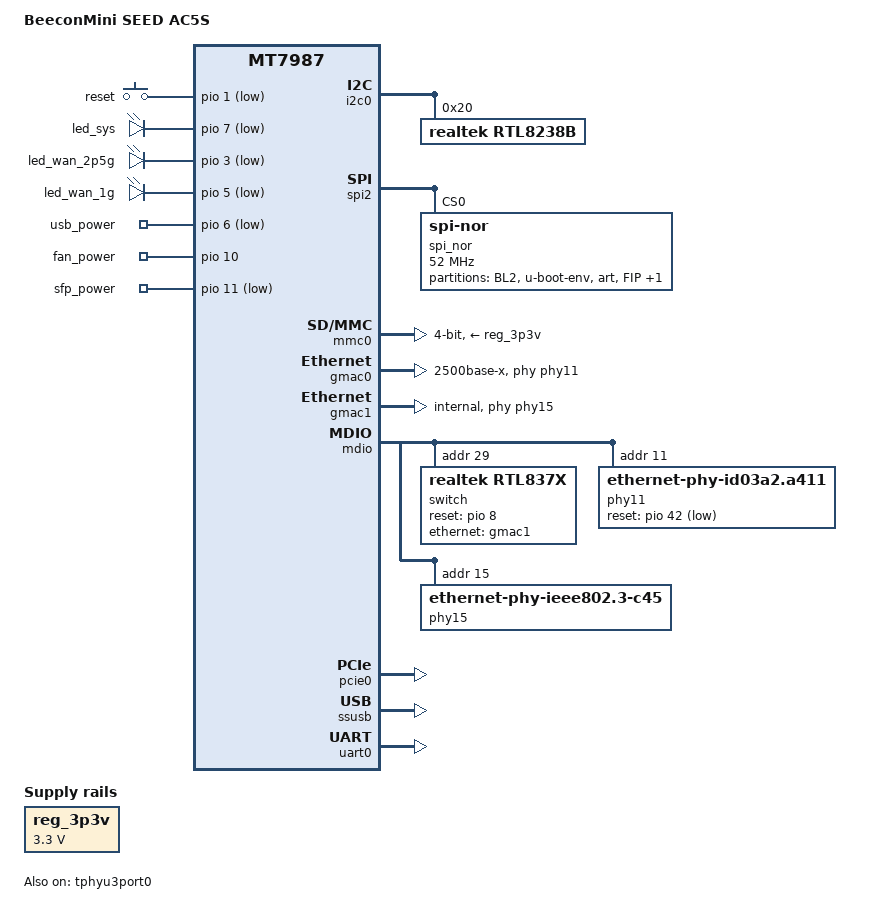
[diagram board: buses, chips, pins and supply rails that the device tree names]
// SPDX-License-Identifier: (GPL-2.0 OR MIT)
//
// BeeconMini SEED AC5S (NOR 变体, 固件放 SPI-NOR) — kernel 6.18 / immortalwrt
// 基准: BeeconMini/immortalwrt 25.12.1 分支同名 DTS
// 改动: 交换芯片节点转换为社区开源驱动 rtl837x-gsw 的绑定

/dts-v1/;
#include "mt7987a.dtsi"
#include <dt-bindings/input/input.h>

/ {
	model = "BeeconMini SEED AC5S";
	compatible = "beeconmini,seed-ac5s-nor", "mediatek,mt7987a", "mediatek,mt7987";

	aliases {
		label-mac-device = &gmac0;
		led-boot = &led_power;
		led-failsafe = &led_power;
		led-running = &led_power;
		led-upgrade = &led_power;
	};

	chosen {
		bootargs = "console=ttyS0,115200n1 \
			    earlycon=uart8250,mmio32,0x11000000 \
			    pci=pcie_bus_perf fstools_ignore_partname=1";
	};

	aliases {
		led-boot = &led_sys;
		led-failsafe = &led_sys;
		led-running = &led_sys;
		led-upgrade = &led_sys;
	};

	gpio-keys {
		compatible = "gpio-keys";

		reset {
			label = "reset";
			linux,code = <KEY_RESTART>;
			gpios = <&pio 1 GPIO_ACTIVE_LOW>;
			debounce-interval = <10>;
		};
	};

	gpio-leds {
		compatible = "gpio-leds";

		led_sys: led@0 {
			label = "led_sys";
			gpios = <&pio 7 GPIO_ACTIVE_LOW>;
		};

		led_wan_2p5g: led@1 {
			label = "led_wan_2p5g";
			gpios = <&pio 3 GPIO_ACTIVE_LOW>;
		};

		led_wan_1g: led@2 {
			label = "led_wan_1g";
			gpios = <&pio 5 GPIO_ACTIVE_LOW>;
		};
	};

	gpio-export {
		compatible = "gpio-export";
		#size-cells = <0>;

		usb {
			gpio-export,name = "usb_power";
			gpio-export,output = <0>;
			gpios = <&pio 6 GPIO_ACTIVE_LOW>;
		};

		fan {
			gpio-export,name = "fan_power";
			gpio-export,output = <0>;
			gpios = <&pio 10 GPIO_ACTIVE_HIGH>;
		};

		sfp {
			gpio-export,name = "sfp_power";
			gpio-export,output = <0>;
			gpios = <&pio 11 GPIO_ACTIVE_LOW>;
		};
	};

	reg_3p3v: regulator-3p3v {
		compatible = "regulator-fixed";
		regulator-name = "fixed-3.3V";
		regulator-min-microvolt = <3300000>;
		regulator-max-microvolt = <3300000>;
		regulator-boot-on;
		regulator-always-on;
	};
};

&i2c0 {
	status = "okay";
	rtl8238b: rtl8238b@20 {
		compatible = "realtek,rtl8238b";
		reg = <0x20>;
	};
};

&spi1 {
	status = "disabled";
};

&spi2 {
	status = "okay";

	spi_nor: spi_nor@0 {
		#address-cells = <1>;
		#size-cells = <1>;
		compatible = "jedec,spi-nor";
		reg = <0>;
		spi-max-frequency = <52000000>;
		spi-tx-bus-width = <4>;
		spi-rx-bus-width = <4>;

		partitions {
			compatible = "fixed-partitions";
			#address-cells = <1>;
			#size-cells = <1>;

			partition@00000 {
				label = "BL2";
				reg = <0x00000 0x0040000>;
				read-only;
			};

			partition@40000 {
				label = "u-boot-env";
				reg = <0x40000 0x0010000>;
			};

			art: partition@50000 {
				label = "art";
				reg = <0x50000 0x0010000>;

				nvmem-layout {
					compatible = "fixed-layout";
					#address-cells = <1>;
					#size-cells = <1>;

					macaddr_base: macaddr@0 {
						reg = <0x0 0x6>;
						compatible = "mac-base";
						#nvmem-cell-cells = <1>;
					};
				};
			};

			partition@60000 {
				label = "FIP";
				reg = <0x60000 0x0200000>;
				read-only;
			};

			partition@260000 {
				compatible = "denx,fit";
				label = "firmware";
				reg = <0x260000 0x1da0000>;
			};
		};
	};
};

&mmc0 {
	pinctrl-names = "default", "state_uhs";
	pinctrl-0 = <&mmc_pins_default>;
	pinctrl-1 = <&mmc_pins_uhs>;
	bus-width = <4>;
	max-frequency = <48000000>;
	cap-sd-highspeed;
	no-mmc;
	no-sdio;
	vmmc-supply = <&reg_3p3v>;
	vqmmc-supply = <&reg_3p3v>;
	status = "okay";
	#address-cells = <1>;
	#size-cells = <0>;
};

&gmac0 {
	compatible = "mediatek,eth-mac";
	reg = <0>;
	mac-type = "gdm";
	phy-mode = "2500base-x";
	phy-handle = <&phy11>;
	status = "okay";
	nvmem-cells = <&macaddr_base 1>;
	nvmem-cell-names = "mac-address";
};

&gmac1 {
	phy-mode = "internal";
	phy-handle = <&phy15>;
	status = "okay";
	nvmem-cells = <&macaddr_base 0>;
	nvmem-cell-names = "mac-address";
};

&mdio {
	/*
	 * RTL8373N 交换芯片 — 社区开源驱动 rtl837x-gsw (kmod-switch-rtl837x)
	 *
	 * 原 BeeconMini 闭源驱动节点:
	 *   rtl8373n { compatible = "realtek,rtl8373n"; mediatek,mdio = <&mdio>;
	 *              mediatek,reset-pin = <&pio 8 GPIO_ACTIVE_HIGH>;
	 *              interrupts = <11 IRQ_TYPE_LEVEL_LOW>; };
	 *
	 * 以下值已于 2026-08-14 实机确认 (官方固件 25.12.3 @ 192.168.10.140):
	 *  - reg = 29 (0x1d): 闭源驱动 rtl8373_smi_read 反汇编硬编码 0x1d;
	 *        邮箱协议读回 chip ID 0x83737000 (= RTL8373N)。总线扫描仅 0x1d
	 *        响应邮箱窗口 (0x15-0x18), 标准 PHY 寄存器不响应。
	 *  - rtl837x,cpu-port = 7: 官方 dmesg "<rtl8373> port:7 link UP - 2.5Gbps";
	 *        上行 gmac1→phy15(内部 2.5G 铜 PHY)→交换芯片电口 7; 且 SDS0/1 均
	 *        配置为 10G 模式 (非上行)。CPU 口不是 serdes 口, 驱动会跳过 serdes 复位。
	 *  - rtl837x,sds0mode = "10g-qxg": 运行态 0x7B20=0x0b4d, SDS0 mode=0xD
	 *        (10GUSXG) + sub-mode 2 — 与开放驱动 "10g-qxg" 写入的字节完全一致
	 *        (SDS0 接 RTL8224N 10G PHY → SFP+ 笼)。
	 *  - SFP+ 默认速率 = 10G: sds0mode "10g-qxg" 固定 (与官方固件一致, 无协商);
	 *        10G 光模块需接对端设备才有 link (无对端无 link 属正常), 2.5G 光模块不协商。
	 *  - rtl837x,sds1mode = "10g-kr": 运行态 SDS1 mode=0x1A (10GR)。
	 *  - reset-gpios: pio8 GPIO_ACTIVE_HIGH — 官方 DTS mediatek,reset-pin=<&pio 8 0>;
	 *        运行态 debugfs gpio-520 "mediatek,reset-pin" out hi (高=运行)。
	 *  - 总线 0x13 有一个未用响应者 (r2=0x1a75, 非邮箱设备), 官方固件不访问;
	 *        与本次集成无关。
	 *  - 10G SFP+ 完整支持 (sfp 节点/8224N) 为后续项, 按 rtl837x-gsw-driver README。
	 */
	switch@1d {
		compatible = "realtek,rtl837x";
		reg = <29>;
		reset-gpios = <&pio 8 GPIO_ACTIVE_HIGH>;
		rtl837x,cpu-port = <7>;
		rtl837x,sds0mode = "10g-qxg";
		rtl837x,sds1mode = "10g-kr";
		ethernet = <&gmac1>;
		status = "okay";
	};

	phy11: phy@11 {
		compatible = "ethernet-phy-id03a2.a411";
		reg = <11>;
		phy-mode = "2500base-x";
		airoha,polarity = <1>;
		airoha,surge = <0>;
		airoha,phy-handle;
		reset-gpios = <&pio 42 GPIO_ACTIVE_LOW>;
		reset-assert-us = <10000>;
		reset-deassert-us = <10000>;
	};

	phy15: phy@15 {
		pinctrl-names = "i2p5gbe-led";
		pinctrl-0 = <&i2p5gbe_led0_pins>;
		compatible = "ethernet-phy-ieee802.3-c45";
		reg = <15>;
		phy-mode = "internal";
	};
};

&pcie0 {
	pinctrl-names = "default";
	pinctrl-0 = <&pcie0_pins>;
	status = "okay";
};

&pcie1 {
	status = "disabled";
};

&ssusb {
	status = "okay";
};

&tphyu3port0 {
	status = "okay";
};

&uart0 {
	pinctrl-names = "default";
	pinctrl-0 = <&uart0_pins>;
	status = "okay";
};
